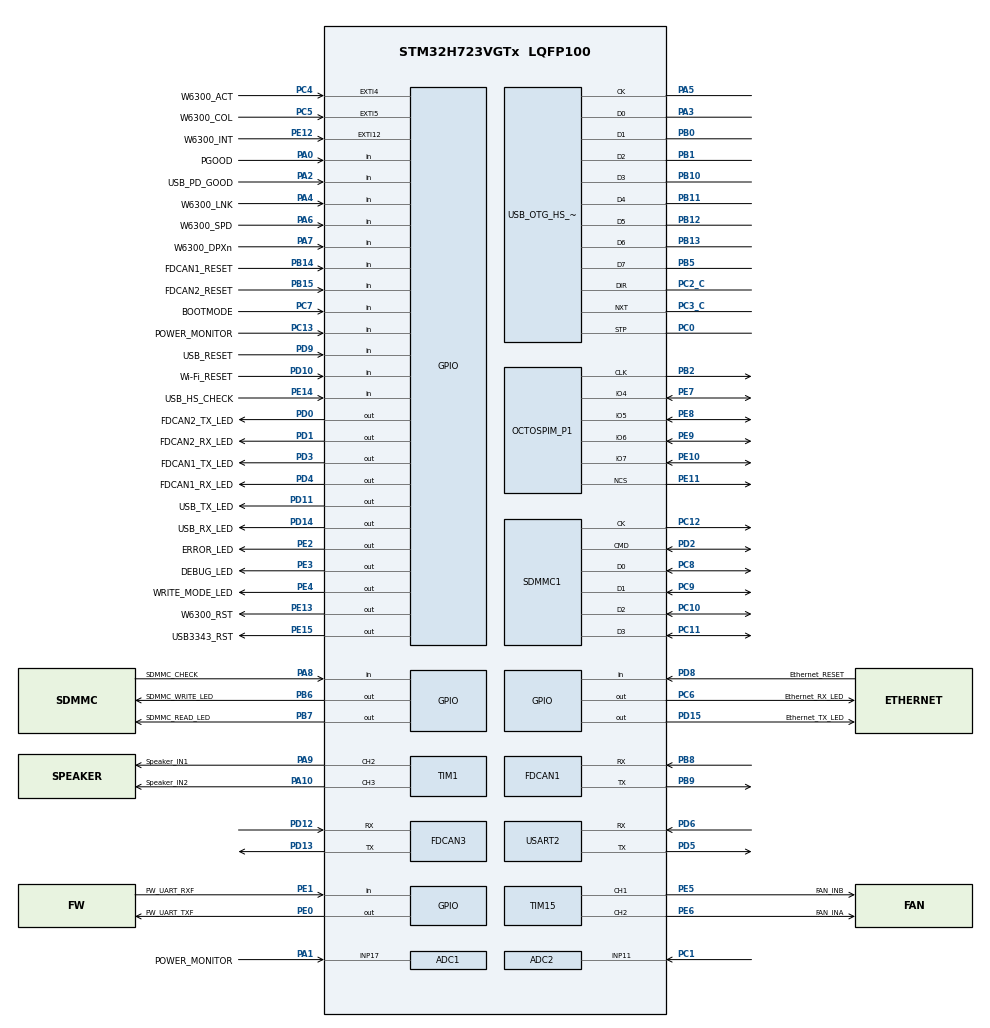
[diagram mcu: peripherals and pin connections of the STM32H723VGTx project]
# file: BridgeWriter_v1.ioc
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ADC1.Channel-0\#ChannelRegularConversion=ADC_CHANNEL_17
ADC1.NbrOfConversionFlag=1
ADC1.OffsetNumber-0\#ChannelRegularConversion=ADC_OFFSET_NONE
ADC1.OffsetSignedSaturation-0\#ChannelRegularConversion=DISABLE
ADC1.Rank-0\#ChannelRegularConversion=1
ADC1.SamplingTime-0\#ChannelRegularConversion=ADC_SAMPLETIME_1CYCLE_5
ADC1.master=1
ADC2.Channel-0\#ChannelRegularConversion=ADC_CHANNEL_11
ADC2.NbrOfConversionFlag=1
ADC2.OffsetNumber-0\#ChannelRegularConversion=ADC_OFFSET_NONE
ADC2.OffsetSignedSaturation-0\#ChannelRegularConversion=DISABLE
ADC2.Rank-0\#ChannelRegularConversion=1
ADC2.SamplingTime-0\#ChannelRegularConversion=ADC_SAMPLETIME_1CYCLE_5
CORTEX_M7.default_mode_Activation=1
FDCAN1.CalculateBaudRateNominal=1000000
FDCAN1.CalculateTimeBitNominal=1000
FDCAN1.CalculateTimeQuantumNominal=50.0
FDCAN1.FrameFormat=FDCAN_FRAME_FD_NO_BRS
FDCAN1.NominalPrescaler=4
FDCAN1.NominalTimeSeg1=15
FDCAN1.NominalTimeSeg2=4
FDCAN1.RxBufferSize=FDCAN_DATA_BYTES_64
FDCAN1.RxFifo0ElmtSize=FDCAN_DATA_BYTES_64
FDCAN1.RxFifo0ElmtsNbr=20
FDCAN1.RxFifo1ElmtSize=FDCAN_DATA_BYTES_64
FDCAN1.RxFifo1ElmtsNbr=20
FDCAN1.TxElmtSize=FDCAN_DATA_BYTES_64
FDCAN1.TxEventsNbr=32
FDCAN3.CalculateBaudRateNominal=1000000
FDCAN3.CalculateTimeBitNominal=1000
FDCAN3.CalculateTimeQuantumNominal=50.0
FDCAN3.FrameFormat=FDCAN_FRAME_FD_NO_BRS
FDCAN3.NominalPrescaler=4
FDCAN3.NominalTimeSeg1=15
FDCAN3.NominalTimeSeg2=4
FDCAN3.RxBufferSize=FDCAN_DATA_BYTES_64
FDCAN3.RxFifo0ElmtSize=FDCAN_DATA_BYTES_64
FDCAN3.RxFifo1ElmtSize=FDCAN_DATA_BYTES_64
FDCAN3.TxElmtSize=FDCAN_DATA_BYTES_64
FDCAN3.TxEventsNbr=32
Mcu.Family=STM32H7
Mcu.Name=STM32H723VGTx
Mcu.Package=LQFP100
NVIC.EXTI15_10_IRQn=true\:0\:0\:false\:false\:true\:true\:true\:true
NVIC.EXTI4_IRQn=true\:0\:0\:false\:false\:true\:true\:true\:true
NVIC.EXTI9_5_IRQn=true\:0\:0\:false\:false\:true\:true\:true\:true
NVIC.FDCAN1_IT0_IRQn=true\:0\:0\:false\:false\:true\:true\:true\:true
NVIC.FDCAN1_IT1_IRQn=true\:0\:0\:false\:false\:true\:true\:true\:true
NVIC.FDCAN3_IT0_IRQn=true\:0\:0\:false\:false\:true\:true\:true\:true
NVIC.FDCAN3_IT1_IRQn=true\:0\:0\:false\:false\:true\:true\:true\:true
NVIC.PriorityGroup=NVIC_PRIORITYGROUP_4
NVIC.RTC_WKUP_IRQn=true\:0\:0\:false\:false\:true\:true\:true\:true
NVIC.TIM6_DAC_IRQn=true\:0\:0\:false\:false\:true\:true\:true\:true
NVIC.TIM7_IRQn=true\:0\:0\:false\:false\:true\:true\:true\:true
PA0.GPIO_Label=PGOOD
PA0.Signal=GPIO_Input
PA1.GPIO_Label=POWER_MONITOR
PA1.Mode=IN17-Single-Ended
PA1.Signal=ADC1_INP17
PA10.GPIO_Label=Speaker_IN2
PA10.GPIO_Speed=GPIO_SPEED_FREQ_MEDIUM
PA10.Signal=S_TIM1_CH3
PA13(JTMS/SWDIO).Mode=Serial_Wire
PA13(JTMS/SWDIO).Signal=DEBUG_JTMS-SWDIO
PA14(JTCK/SWCLK).Mode=Serial_Wire
PA14(JTCK/SWCLK).Signal=DEBUG_JTCK-SWCLK
PA2.GPIO_Label=USB_PD_GOOD
PA2.Signal=GPIO_Input
PA3.Mode=Device_HS
PA3.Signal=USB_OTG_HS_ULPI_D0
PA4.GPIO_Label=W6300_LNK
PA4.Signal=GPIO_Input
PA5.Mode=Device_HS
PA5.Signal=USB_OTG_HS_ULPI_CK
PA6.GPIO_Label=W6300_SPD
PA6.Signal=GPIO_Input
PA7.GPIO_Label=W6300_DPXn
PA7.Signal=GPIO_Input
PA8.GPIO_Label=SDMMC_CHECK
PA8.Signal=GPIO_Input
PA9.GPIO_Label=Speaker_IN1
PA9.GPIO_Speed=GPIO_SPEED_FREQ_MEDIUM
PA9.Signal=S_TIM1_CH2
PB0.Mode=Device_HS
PB0.Signal=USB_OTG_HS_ULPI_D1
PB1.Mode=Device_HS
PB1.Signal=USB_OTG_HS_ULPI_D2
PB10.Mode=Device_HS
PB10.Signal=USB_OTG_HS_ULPI_D3
PB11.Mode=Device_HS
PB11.Signal=USB_OTG_HS_ULPI_D4
PB12.Mode=Device_HS
PB12.Signal=USB_OTG_HS_ULPI_D5
PB13.Mode=Device_HS
PB13.Signal=USB_OTG_HS_ULPI_D6
PB14.GPIO_Label=FDCAN1_RESET
PB14.Signal=GPIO_Input
PB15.GPIO_Label=FDCAN2_RESET
PB15.Signal=GPIO_Input
PB2.Mode=O1_P1_CLK
PB2.Signal=OCTOSPIM_P1_CLK
PB5.Mode=Device_HS
PB5.Signal=USB_OTG_HS_ULPI_D7
PB6.GPIO_Label=SDMMC_WRITE_LED
PB6.Signal=GPIO_Output
PB7.GPIO_Label=SDMMC_READ_LED
PB7.Signal=GPIO_Output
PB8.Mode=FDCAN_Activate
PB8.Signal=FDCAN1_RX
PB9.Mode=FDCAN_Activate
PB9.Signal=FDCAN1_TX
PC0.Mode=Device_HS
PC0.Signal=USB_OTG_HS_ULPI_STP
PC1.Signal=ADCx_INP11
PC10.Mode=SD_4_bits_Wide_bus
PC10.Signal=SDMMC1_D2
PC11.Mode=SD_4_bits_Wide_bus
PC11.Signal=SDMMC1_D3
PC12.Mode=SD_4_bits_Wide_bus
PC12.Signal=SDMMC1_CK
PC13.GPIO_Label=POWER_MONITOR
PC13.Signal=GPIO_Input
PC14-OSC32_IN.Mode=LSE-External-Oscillator
PC14-OSC32_IN.Signal=RCC_OSC32_IN
PC15-OSC32_OUT.Mode=LSE-External-Oscillator
PC15-OSC32_OUT.Signal=RCC_OSC32_OUT
PC2_C.Mode=Device_HS
PC2_C.Signal=USB_OTG_HS_ULPI_DIR
PC3_C.Mode=Device_HS
PC3_C.Signal=USB_OTG_HS_ULPI_NXT
PC4.GPIO_Label=W6300_ACT
PC4.GPIO_ModeDefaultEXTI=GPIO_MODE_IT_RISING_FALLING
PC4.Signal=GPXTI4
PC5.GPIO_Label=W6300_COL
PC5.Signal=GPXTI5
PC6.GPIO_Label=Ethernet_RX_LED
PC6.Signal=GPIO_Output
PC7.GPIO_Label=BOOTMODE
PC7.Signal=GPIO_Input
PC8.Mode=SD_4_bits_Wide_bus
PC8.Signal=SDMMC1_D0
PC9.Mode=SD_4_bits_Wide_bus
PC9.Signal=SDMMC1_D1
PD0.GPIO_Label=FDCAN2_TX_LED
PD0.Signal=GPIO_Output
PD1.GPIO_Label=FDCAN2_RX_LED
PD1.Signal=GPIO_Output
PD10.GPIO_Label=Wi-Fi_RESET
PD10.Signal=GPIO_Input
PD11.GPIO_Label=USB_TX_LED
PD11.Signal=GPIO_Output
PD12.Mode=FDCAN_Activate
PD12.Signal=FDCAN3_RX
PD13.Mode=FDCAN_Activate
PD13.Signal=FDCAN3_TX
PD14.GPIO_Label=USB_RX_LED
PD14.Signal=GPIO_Output
PD15.GPIO_Label=Ethernet_TX_LED
PD15.Signal=GPIO_Output
PD2.Mode=SD_4_bits_Wide_bus
PD2.Signal=SDMMC1_CMD
PD3.GPIO_Label=FDCAN1_TX_LED
PD3.Signal=GPIO_Output
PD4.GPIO_Label=FDCAN1_RX_LED
PD4.Signal=GPIO_Output
PD5.Mode=Asynchronous
PD5.Signal=USART2_TX
PD6.Mode=Asynchronous
PD6.Signal=USART2_RX
PD8.GPIO_Label=Ethernet_RESET
PD8.Signal=GPIO_Input
PD9.GPIO_Label=USB_RESET
PD9.Signal=GPIO_Input
PE0.GPIO_Label=FW_UART_TXF
PE0.GPIO_Speed=GPIO_SPEED_FREQ_VERY_HIGH
PE0.Signal=GPIO_Output
PE1.GPIO_Label=FW_UART_RXF
PE1.Signal=GPIO_Input
PE10.Mode=OCTOSPI1_IOL_Port1H
PE10.Signal=OCTOSPIM_P1_IO7
PE11.Mode=OCTOSPI1_Port1_NCS
PE11.Signal=OCTOSPIM_P1_NCS
PE12.GPIO_Label=W6300_INT
PE12.GPIO_ModeDefaultEXTI=GPIO_MODE_IT_RISING_FALLING
PE12.Signal=GPXTI12
PE13.GPIO_Label=W6300_RST
PE13.GPIO_Speed=GPIO_SPEED_FREQ_VERY_HIGH
PE13.Signal=GPIO_Output
PE14.GPIO_Label=USB_HS_CHECK
PE14.Signal=GPIO_Input
PE15.GPIO_Label=USB3343_RST
PE15.GPIO_Speed=GPIO_SPEED_FREQ_VERY_HIGH
PE15.Signal=GPIO_Output
PE2.GPIO_Label=ERROR_LED
PE2.Signal=GPIO_Output
PE3.GPIO_Label=DEBUG_LED
PE3.Signal=GPIO_Output
PE4.GPIO_Label=WRITE_MODE_LED
PE4.Signal=GPIO_Output
PE5.GPIO_Label=FAN_INB
PE5.GPIO_Speed=GPIO_SPEED_FREQ_MEDIUM
PE5.Signal=S_TIM15_CH1
PE6.GPIO_Label=FAN_INA
PE6.GPIO_Speed=GPIO_SPEED_FREQ_MEDIUM
PE6.Signal=S_TIM15_CH2
PE7.Mode=OCTOSPI1_IOL_Port1H
PE7.Signal=OCTOSPIM_P1_IO4
PE8.Mode=OCTOSPI1_IOL_Port1H
PE8.Signal=OCTOSPIM_P1_IO5
PE9.Mode=OCTOSPI1_IOL_Port1H
PE9.Signal=OCTOSPIM_P1_IO6
PH0-OSC_IN.Mode=HSE-External-Clock-Source
PH0-OSC_IN.Signal=RCC_OSC_IN
ProjectManager.HeapSize=0x200
ProjectManager.StackSize=0x400
ProjectManager.TargetToolchain=CMake
RCC.ADCCLockSelection=RCC_ADCCLKSOURCE_CLKP
RCC.ADCFreq_Value=64000000
RCC.APB1Freq_Value=137500000
RCC.APB2Freq_Value=137500000
RCC.APB3Freq_Value=137500000
RCC.APB4Freq_Value=137500000
RCC.CSI_VALUE=4000000
RCC.CortexFreq_Value=550000000
RCC.Cortex_Div=SYSTICK_CLKSOURCE_HCLK
RCC.D1CPRE=RCC_SYSCLK_DIV1
RCC.D1PPRE=RCC_APB3_DIV2
RCC.D2PPRE1=RCC_APB1_DIV2
RCC.D2PPRE2=RCC_APB2_DIV2
RCC.D3PPRE=RCC_APB4_DIV2
RCC.DFSDMCLockSelection=RCC_DFSDM1CLKSOURCE_D2PCLK1
RCC.DIVM1=5
RCC.DIVM2=5
RCC.DIVM3=5
RCC.DIVN1=55
RCC.DIVN2=48
RCC.DIVN3=48
RCC.DIVP1=1
RCC.DIVP2=2
RCC.DIVP3=2
RCC.DIVQ1=2
RCC.DIVQ2=6
RCC.DIVQ3=4
RCC.DIVR1=2
RCC.DIVR2=2
RCC.DIVR3=2
RCC.EXTERNAL_CLOCK_VALUE=12288000
RCC.FDCANCLockSelection=RCC_FDCANCLKSOURCE_PLL2
RCC.FMCCLockSelection=RCC_FMCCLKSOURCE_D1HCLK
RCC.HCLKFreq_Value=275000000
RCC.HPRE=RCC_HCLK_DIV2
RCC.HSE_VALUE=50000000
RCC.HSI_VALUE=64000000
RCC.LPTIM1CLockSelection=RCC_LPTIM1CLKSOURCE_D2PCLK1
RCC.LPTIM2CLockSelection=RCC_LPTIM2CLKSOURCE_D3PCLK1
RCC.LPUART1CLockSelection=RCC_LPUART1CLKSOURCE_HSI
RCC.PLLSourceVirtual=RCC_PLLSOURCE_HSE
RCC.QSPICLockSelection=RCC_OSPICLKSOURCE_PLL2
RCC.RCC_MCO1Source=RCC_MCO1SOURCE_HSI
RCC.RTCClockSelection=RCC_RTCCLKSOURCE_LSE
RCC.SAI4ACLockSelection=RCC_SAI4ACLKSOURCE_PLL
RCC.SAI4BCLockSelection=RCC_SAI4BCLKSOURCE_PLL
RCC.SDMMC1CLockSelection=RCC_SDMMCCLKSOURCE_PLL2
RCC.SPI123CLockSelection=RCC_SPI123CLKSOURCE_PLL
RCC.SPI6CLockSelection=RCC_SPI6CLKSOURCE_D3PCLK1
RCC.SYSCLKFreq_VALUE=550000000
RCC.SYSCLKSource=RCC_SYSCLKSOURCE_PLLCLK
RCC.Spi45ClockSelection=RCC_SPI45CLKSOURCE_D2PCLK1
RCC.USART234578CLockSelection=RCC_USART234578CLKSOURCE_PLL3
RCC.USBCLockSelection=RCC_USBCLKSOURCE_HSI48
RCC.USBFreq_Value=48000000
RTC.WakeUpClock-WakeUp=RTC_WAKEUPCLOCK_CK_SPRE_16BITS
SH.ADCx_INP11.0=ADC2_INP11,IN11-Single-Ended
SH.S_TIM15_CH1.0=TIM15_CH1,PWM Generation1 CH1
SH.S_TIM15_CH2.0=TIM15_CH2,PWM Generation2 CH2
SH.S_TIM1_CH2.0=TIM1_CH2,PWM Generation2 CH2
SH.S_TIM1_CH3.0=TIM1_CH3,PWM Generation3 CH3
TIM1.Channel-PWM\ Generation2\ CH2=TIM_CHANNEL_2
TIM1.Channel-PWM\ Generation3\ CH3=TIM_CHANNEL_3
TIM15.Channel-PWM\ Generation1\ CH1=TIM_CHANNEL_1
TIM15.Channel-PWM\ Generation2\ CH2=TIM_CHANNEL_2
TIM6.Period=1000
TIM6.Prescaler=275
TIM7.Period=20
TIM7.Prescaler=275
USART2.VirtualMode-Asynchronous=VM_ASYNC
USB_OTG_HS.VirtualMode-Device_HS=Device_HS
VP_MEMORYMAP_VS_MEMORYMAP.Mode=CurAppReg
VP_OCTOSPI1_VS_octo.Mode=octo_mode
VP_RTC_VS_RTC_Activate.Mode=RTC_Enabled
VP_RTC_VS_RTC_WakeUp_intern.Mode=WakeUp
VP_TIM6_VS_ClockSourceINT.Mode=Enable_Timer
VP_TIM7_VS_ClockSourceINT.Mode=Enable_Timer
board=custom

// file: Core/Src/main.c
/* USER CODE BEGIN Header */
/**
  ******************************************************************************
  * @file           : main.c
  * @brief          : Main program body
  ******************************************************************************
  * @attention
  *
  * Copyright (c) 2026 STMicroelectronics.
  * All rights reserved.
  *
  * This software is licensed under terms that can be found in the LICENSE file
  * in the root directory of this software component.
  * If no LICENSE file comes with this software, it is provided AS-IS.
  *
  ******************************************************************************
  */
/* USER CODE END Header */
#include "main.h"

/* USER CODE BEGIN Includes */
#include "HEADER_INCLUDE.h"
/* USER CODE END Includes */

ADC_HandleTypeDef hadc1;
ADC_HandleTypeDef hadc2;

FDCAN_HandleTypeDef hfdcan1;
FDCAN_HandleTypeDef hfdcan3;

OSPI_HandleTypeDef hospi1;

RTC_HandleTypeDef hrtc;

SD_HandleTypeDef hsd1;

TIM_HandleTypeDef htim1;
TIM_HandleTypeDef htim6;
TIM_HandleTypeDef htim7;
TIM_HandleTypeDef htim15;

UART_HandleTypeDef huart2;

PCD_HandleTypeDef hpcd_USB_OTG_HS;

void SystemClock_Config(void);
void PeriphCommonClock_Config(void);
static void MPU_Config(void);
static void MX_GPIO_Init(void);
static void MX_FDCAN1_Init(void);
static void MX_FDCAN3_Init(void);
static void MX_OCTOSPI1_Init(void);
static void MX_RTC_Init(void);
static void MX_SDMMC1_SD_Init(void);
static void MX_USB_OTG_HS_PCD_Init(void);
static void MX_ADC1_Init(void);
static void MX_ADC2_Init(void);
static void MX_USART2_UART_Init(void);
static void MX_TIM1_Init(void);
static void MX_TIM6_Init(void);
static void MX_TIM7_Init(void);
static void MX_TIM15_Init(void);

int main(void)
{

  /* MPU Configuration--------------------------------------------------------*/
  MPU_Config();

  /* MCU Configuration--------------------------------------------------------*/

  /* Reset of all peripherals, Initializes the Flash interface and the Systick. */
  HAL_Init();

  /* Configure the system clock */
  SystemClock_Config();

  /* Configure the peripherals common clocks */
  PeriphCommonClock_Config();

  /* Initialize all configured peripherals */
  MX_GPIO_Init();
  MX_FDCAN1_Init();
  MX_FDCAN3_Init();
  MX_OCTOSPI1_Init();
  MX_RTC_Init();
  MX_SDMMC1_SD_Init();
  MX_USB_OTG_HS_PCD_Init();
  MX_ADC1_Init();
  MX_ADC2_Init();
  MX_USART2_UART_Init();
  MX_TIM1_Init();
  MX_TIM6_Init();
  MX_TIM7_Init();
  MX_TIM15_Init();
  /* USER CODE BEGIN 2 */
  Maidui3_Setup();
  /* USER CODE END 2 */

  /* Infinite loop */
  while (1)
  {

  }
}

void SystemClock_Config(void)
{
  RCC_OscInitTypeDef RCC_OscInitStruct = {0};
  RCC_ClkInitTypeDef RCC_ClkInitStruct = {0};

  /** Supply configuration update enable
  */
  HAL_PWREx_ConfigSupply(PWR_LDO_SUPPLY);

  /** Configure the main internal regulator output voltage
  */
  __HAL_PWR_VOLTAGESCALING_CONFIG(PWR_REGULATOR_VOLTAGE_SCALE0);

  while(!__HAL_PWR_GET_FLAG(PWR_FLAG_VOSRDY)) {}

  /** Configure LSE Drive Capability
  */
  HAL_PWR_EnableBkUpAccess();
  __HAL_RCC_LSEDRIVE_CONFIG(RCC_LSEDRIVE_LOW);

  /** Initializes the RCC Oscillators according to the specified parameters
  * in the RCC_OscInitTypeDef structure.
  */
  RCC_OscInitStruct.OscillatorType = RCC_OSCILLATORTYPE_HSI48|RCC_OSCILLATORTYPE_HSI
                              |RCC_OSCILLATORTYPE_HSE|RCC_OSCILLATORTYPE_LSE;
  RCC_OscInitStruct.HSEState = RCC_HSE_BYPASS;
  RCC_OscInitStruct.LSEState = RCC_LSE_ON;
  RCC_OscInitStruct.HSIState = RCC_HSI_DIV1;
  RCC_OscInitStruct.HSICalibrationValue = 64;
  RCC_OscInitStruct.HSI48State = RCC_HSI48_ON;
  RCC_OscInitStruct.PLL.PLLState = RCC_PLL_ON;
  RCC_OscInitStruct.PLL.PLLSource = RCC_PLLSOURCE_HSE;
  RCC_OscInitStruct.PLL.PLLM = 5;
  RCC_OscInitStruct.PLL.PLLN = 55;
  RCC_OscInitStruct.PLL.PLLP = 1;
  RCC_OscInitStruct.PLL.PLLQ = 2;
  RCC_OscInitStruct.PLL.PLLR = 2;
  RCC_OscInitStruct.PLL.PLLRGE = RCC_PLL1VCIRANGE_3;
  RCC_OscInitStruct.PLL.PLLVCOSEL = RCC_PLL1VCOWIDE;
  RCC_OscInitStruct.PLL.PLLFRACN = 0;
  if (HAL_RCC_OscConfig(&RCC_OscInitStruct) != HAL_OK)
  {
    Error_Handler();
  }

  /** Initializes the CPU, AHB and APB buses clocks
  */
  RCC_ClkInitStruct.ClockType = RCC_CLOCKTYPE_HCLK|RCC_CLOCKTYPE_SYSCLK
                              |RCC_CLOCKTYPE_PCLK1|RCC_CLOCKTYPE_PCLK2
                              |RCC_CLOCKTYPE_D3PCLK1|RCC_CLOCKTYPE_D1PCLK1;
  RCC_ClkInitStruct.SYSCLKSource = RCC_SYSCLKSOURCE_PLLCLK;
  RCC_ClkInitStruct.SYSCLKDivider = RCC_SYSCLK_DIV1;
  RCC_ClkInitStruct.AHBCLKDivider = RCC_HCLK_DIV2;
  RCC_ClkInitStruct.APB3CLKDivider = RCC_APB3_DIV2;
  RCC_ClkInitStruct.APB1CLKDivider = RCC_APB1_DIV2;
  RCC_ClkInitStruct.APB2CLKDivider = RCC_APB2_DIV2;
  RCC_ClkInitStruct.APB4CLKDivider = RCC_APB4_DIV2;

  if (HAL_RCC_ClockConfig(&RCC_ClkInitStruct, FLASH_LATENCY_3) != HAL_OK)
  {
    Error_Handler();
  }
}

void PeriphCommonClock_Config(void)
{
  RCC_PeriphCLKInitTypeDef PeriphClkInitStruct = {0};

  /** Initializes the peripherals clock
  */
  PeriphClkInitStruct.PeriphClockSelection = RCC_PERIPHCLK_OSPI|RCC_PERIPHCLK_SDMMC
                              |RCC_PERIPHCLK_FDCAN|RCC_PERIPHCLK_CKPER;
  PeriphClkInitStruct.PLL2.PLL2M = 5;
  PeriphClkInitStruct.PLL2.PLL2N = 48;
  PeriphClkInitStruct.PLL2.PLL2P = 2;
  PeriphClkInitStruct.PLL2.PLL2Q = 6;
  PeriphClkInitStruct.PLL2.PLL2R = 2;
  PeriphClkInitStruct.PLL2.PLL2RGE = RCC_PLL2VCIRANGE_3;
  PeriphClkInitStruct.PLL2.PLL2VCOSEL = RCC_PLL2VCOWIDE;
  PeriphClkInitStruct.PLL2.PLL2FRACN = 0;
  PeriphClkInitStruct.OspiClockSelection = RCC_OSPICLKSOURCE_PLL2;
  PeriphClkInitStruct.SdmmcClockSelection = RCC_SDMMCCLKSOURCE_PLL2;
  PeriphClkInitStruct.CkperClockSelection = RCC_CLKPSOURCE_HSI;
  PeriphClkInitStruct.FdcanClockSelection = RCC_FDCANCLKSOURCE_PLL2;
  if (HAL_RCCEx_PeriphCLKConfig(&PeriphClkInitStruct) != HAL_OK)
  {
    Error_Handler();
  }
}

static void MX_ADC1_Init(void)
{

  ADC_MultiModeTypeDef multimode = {0};
  ADC_ChannelConfTypeDef sConfig = {0};

  /** Common config
  */
  hadc1.Instance = ADC1;
  hadc1.Init.ClockPrescaler = ADC_CLOCK_ASYNC_DIV1;
  hadc1.Init.Resolution = ADC_RESOLUTION_16B;
  hadc1.Init.ScanConvMode = ADC_SCAN_DISABLE;
  hadc1.Init.EOCSelection = ADC_EOC_SINGLE_CONV;
  hadc1.Init.LowPowerAutoWait = DISABLE;
  hadc1.Init.ContinuousConvMode = DISABLE;
  hadc1.Init.NbrOfConversion = 1;
  hadc1.Init.DiscontinuousConvMode = DISABLE;
  hadc1.Init.ExternalTrigConv = ADC_SOFTWARE_START;
  hadc1.Init.ExternalTrigConvEdge = ADC_EXTERNALTRIGCONVEDGE_NONE;
  hadc1.Init.ConversionDataManagement = ADC_CONVERSIONDATA_DR;
  hadc1.Init.Overrun = ADC_OVR_DATA_PRESERVED;
  hadc1.Init.LeftBitShift = ADC_LEFTBITSHIFT_NONE;
  hadc1.Init.OversamplingMode = DISABLE;
  hadc1.Init.Oversampling.Ratio = 1;
  if (HAL_ADC_Init(&hadc1) != HAL_OK)
  {
    Error_Handler();
  }

  /** Configure the ADC multi-mode
  */
  multimode.Mode = ADC_MODE_INDEPENDENT;
  if (HAL_ADCEx_MultiModeConfigChannel(&hadc1, &multimode) != HAL_OK)
  {
    Error_Handler();
  }

  /** Configure Regular Channel
  */
  sConfig.Channel = ADC_CHANNEL_17;
  sConfig.Rank = ADC_REGULAR_RANK_1;
  sConfig.SamplingTime = ADC_SAMPLETIME_1CYCLE_5;
  sConfig.SingleDiff = ADC_SINGLE_ENDED;
  sConfig.OffsetNumber = ADC_OFFSET_NONE;
  sConfig.Offset = 0;
  sConfig.OffsetSignedSaturation = DISABLE;
  if (HAL_ADC_ConfigChannel(&hadc1, &sConfig) != HAL_OK)
  {
    Error_Handler();
  }

}

static void MX_ADC2_Init(void)
{

  ADC_ChannelConfTypeDef sConfig = {0};

  /** Common config
  */
  hadc2.Instance = ADC2;
  hadc2.Init.ClockPrescaler = ADC_CLOCK_ASYNC_DIV1;
  hadc2.Init.Resolution = ADC_RESOLUTION_16B;
  hadc2.Init.ScanConvMode = ADC_SCAN_DISABLE;
  hadc2.Init.EOCSelection = ADC_EOC_SINGLE_CONV;
  hadc2.Init.LowPowerAutoWait = DISABLE;
  hadc2.Init.ContinuousConvMode = DISABLE;
  hadc2.Init.NbrOfConversion = 1;
  hadc2.Init.DiscontinuousConvMode = DISABLE;
  hadc2.Init.ExternalTrigConv = ADC_SOFTWARE_START;
  hadc2.Init.ExternalTrigConvEdge = ADC_EXTERNALTRIGCONVEDGE_NONE;
  hadc2.Init.ConversionDataManagement = ADC_CONVERSIONDATA_DR;
  hadc2.Init.Overrun = ADC_OVR_DATA_PRESERVED;
  hadc2.Init.LeftBitShift = ADC_LEFTBITSHIFT_NONE;
  hadc2.Init.OversamplingMode = DISABLE;
  hadc2.Init.Oversampling.Ratio = 1;
  if (HAL_ADC_Init(&hadc2) != HAL_OK)
  {
    Error_Handler();
  }

  /** Configure Regular Channel
  */
  sConfig.Channel = ADC_CHANNEL_11;
  sConfig.Rank = ADC_REGULAR_RANK_1;
  sConfig.SamplingTime = ADC_SAMPLETIME_1CYCLE_5;
  sConfig.SingleDiff = ADC_SINGLE_ENDED;
  sConfig.OffsetNumber = ADC_OFFSET_NONE;
  sConfig.Offset = 0;
  sConfig.OffsetSignedSaturation = DISABLE;
  if (HAL_ADC_ConfigChannel(&hadc2, &sConfig) != HAL_OK)
  {
    Error_Handler();
  }

}

static void MX_FDCAN1_Init(void)
{

  hfdcan1.Instance = FDCAN1;
  hfdcan1.Init.FrameFormat = FDCAN_FRAME_FD_NO_BRS;
  hfdcan1.Init.Mode = FDCAN_MODE_NORMAL;
  hfdcan1.Init.AutoRetransmission = DISABLE;
  hfdcan1.Init.TransmitPause = DISABLE;
  hfdcan1.Init.ProtocolException = DISABLE;
  hfdcan1.Init.NominalPrescaler = 4;
  hfdcan1.Init.NominalSyncJumpWidth = 1;
  hfdcan1.Init.NominalTimeSeg1 = 15;
  hfdcan1.Init.NominalTimeSeg2 = 4;
  hfdcan1.Init.DataPrescaler = 1;
  hfdcan1.Init.DataSyncJumpWidth = 1;
  hfdcan1.Init.DataTimeSeg1 = 1;
  hfdcan1.Init.DataTimeSeg2 = 1;
  hfdcan1.Init.MessageRAMOffset = 0;
  hfdcan1.Init.StdFiltersNbr = 0;
  hfdcan1.Init.ExtFiltersNbr = 0;
  hfdcan1.Init.RxFifo0ElmtsNbr = 20;
  hfdcan1.Init.RxFifo0ElmtSize = FDCAN_DATA_BYTES_64;
  hfdcan1.Init.RxFifo1ElmtsNbr = 20;
  hfdcan1.Init.RxFifo1ElmtSize = FDCAN_DATA_BYTES_64;
  hfdcan1.Init.RxBuffersNbr = 0;
  hfdcan1.Init.RxBufferSize = FDCAN_DATA_BYTES_64;
  hfdcan1.Init.TxEventsNbr = 32;
  hfdcan1.Init.TxBuffersNbr = 0;
  hfdcan1.Init.TxFifoQueueElmtsNbr = 0;
  hfdcan1.Init.TxFifoQueueMode = FDCAN_TX_FIFO_OPERATION;
  hfdcan1.Init.TxElmtSize = FDCAN_DATA_BYTES_64;
  if (HAL_FDCAN_Init(&hfdcan1) != HAL_OK)
  {
    Error_Handler();
  }

}

static void MX_FDCAN3_Init(void)
{

  hfdcan3.Instance = FDCAN3;
  hfdcan3.Init.FrameFormat = FDCAN_FRAME_FD_NO_BRS;
  hfdcan3.Init.Mode = FDCAN_MODE_NORMAL;
  hfdcan3.Init.AutoRetransmission = DISABLE;
  hfdcan3.Init.TransmitPause = DISABLE;
  hfdcan3.Init.ProtocolException = DISABLE;
  hfdcan3.Init.NominalPrescaler = 4;
  hfdcan3.Init.NominalSyncJumpWidth = 1;
  hfdcan3.Init.NominalTimeSeg1 = 15;
  hfdcan3.Init.NominalTimeSeg2 = 4;
  hfdcan3.Init.DataPrescaler = 1;
  hfdcan3.Init.DataSyncJumpWidth = 1;
  hfdcan3.Init.DataTimeSeg1 = 1;
  hfdcan3.Init.DataTimeSeg2 = 1;
  hfdcan3.Init.MessageRAMOffset = 0;
  hfdcan3.Init.StdFiltersNbr = 0;
  hfdcan3.Init.ExtFiltersNbr = 0;
  hfdcan3.Init.RxFifo0ElmtsNbr = 0;
  hfdcan3.Init.RxFifo0ElmtSize = FDCAN_DATA_BYTES_64;
  hfdcan3.Init.RxFifo1ElmtsNbr = 0;
  hfdcan3.Init.RxFifo1ElmtSize = FDCAN_DATA_BYTES_64;
  hfdcan3.Init.RxBuffersNbr = 0;
  hfdcan3.Init.RxBufferSize = FDCAN_DATA_BYTES_64;
  hfdcan3.Init.TxEventsNbr = 32;
  hfdcan3.Init.TxBuffersNbr = 0;
  hfdcan3.Init.TxFifoQueueElmtsNbr = 0;
  hfdcan3.Init.TxFifoQueueMode = FDCAN_TX_FIFO_OPERATION;
  hfdcan3.Init.TxElmtSize = FDCAN_DATA_BYTES_64;
  if (HAL_FDCAN_Init(&hfdcan3) != HAL_OK)
  {
    Error_Handler();
  }

}

static void MX_OCTOSPI1_Init(void)
{

  OSPIM_CfgTypeDef sOspiManagerCfg = {0};

  /* OCTOSPI1 parameter configuration*/
  hospi1.Instance = OCTOSPI1;
  hospi1.Init.FifoThreshold = 1;
  hospi1.Init.DualQuad = HAL_OSPI_DUALQUAD_DISABLE;
  hospi1.Init.MemoryType = HAL_OSPI_MEMTYPE_MICRON;
  hospi1.Init.DeviceSize = 32;
  hospi1.Init.ChipSelectHighTime = 1;
  hospi1.Init.FreeRunningClock = HAL_OSPI_FREERUNCLK_DISABLE;
  hospi1.Init.ClockMode = HAL_OSPI_CLOCK_MODE_0;
  hospi1.Init.WrapSize = HAL_OSPI_WRAP_NOT_SUPPORTED;
  hospi1.Init.ClockPrescaler = 1;
  hospi1.Init.SampleShifting = HAL_OSPI_SAMPLE_SHIFTING_NONE;
  hospi1.Init.DelayHoldQuarterCycle = HAL_OSPI_DHQC_DISABLE;
  hospi1.Init.ChipSelectBoundary = 0;
  hospi1.Init.DelayBlockBypass = HAL_OSPI_DELAY_BLOCK_BYPASSED;
  hospi1.Init.MaxTran = 0;
  hospi1.Init.Refresh = 0;
  if (HAL_OSPI_Init(&hospi1) != HAL_OK)
  {
    Error_Handler();
  }
  sOspiManagerCfg.ClkPort = 1;
  sOspiManagerCfg.NCSPort = 1;
  sOspiManagerCfg.IOLowPort = HAL_OSPIM_IOPORT_1_HIGH;
  if (HAL_OSPIM_Config(&hospi1, &sOspiManagerCfg, HAL_OSPI_TIMEOUT_DEFAULT_VALUE) != HAL_OK)
  {
    Error_Handler();
  }

}

static void MX_RTC_Init(void)
{

  /** Initialize RTC Only
  */
  hrtc.Instance = RTC;
  hrtc.Init.HourFormat = RTC_HOURFORMAT_24;
  hrtc.Init.AsynchPrediv = 127;
  hrtc.Init.SynchPrediv = 255;
  hrtc.Init.OutPut = RTC_OUTPUT_DISABLE;
  hrtc.Init.OutPutPolarity = RTC_OUTPUT_POLARITY_HIGH;
  hrtc.Init.OutPutType = RTC_OUTPUT_TYPE_OPENDRAIN;
  hrtc.Init.OutPutRemap = RTC_OUTPUT_REMAP_NONE;
  if (HAL_RTC_Init(&hrtc) != HAL_OK)
  {
    Error_Handler();
  }

  /** Enable the WakeUp
  */
  if (HAL_RTCEx_SetWakeUpTimer_IT(&hrtc, 0, RTC_WAKEUPCLOCK_CK_SPRE_16BITS) != HAL_OK)
  {
    Error_Handler();
  }

}

static void MX_SDMMC1_SD_Init(void)
{

  hsd1.Instance = SDMMC1;
  hsd1.Init.ClockEdge = SDMMC_CLOCK_EDGE_RISING;
  hsd1.Init.ClockPowerSave = SDMMC_CLOCK_POWER_SAVE_DISABLE;
  hsd1.Init.BusWide = SDMMC_BUS_WIDE_4B;
  hsd1.Init.HardwareFlowControl = SDMMC_HARDWARE_FLOW_CONTROL_DISABLE;
  hsd1.Init.ClockDiv = 0;
  if (HAL_SD_Init(&hsd1) != HAL_OK)
  {
    Error_Handler();
  }

}

static void MX_TIM1_Init(void)
{

  TIM_MasterConfigTypeDef sMasterConfig = {0};
  TIM_OC_InitTypeDef sConfigOC = {0};
  TIM_BreakDeadTimeConfigTypeDef sBreakDeadTimeConfig = {0};

  htim1.Instance = TIM1;
  htim1.Init.Prescaler = 0;
  htim1.Init.CounterMode = TIM_COUNTERMODE_UP;
  htim1.Init.Period = 65535;
  htim1.Init.ClockDivision = TIM_CLOCKDIVISION_DIV1;
  htim1.Init.RepetitionCounter = 0;
  htim1.Init.AutoReloadPreload = TIM_AUTORELOAD_PRELOAD_DISABLE;
  if (HAL_TIM_PWM_Init(&htim1) != HAL_OK)
  {
    Error_Handler();
  }
  sMasterConfig.MasterOutputTrigger = TIM_TRGO_RESET;
  sMasterConfig.MasterOutputTrigger2 = TIM_TRGO2_RESET;
  sMasterConfig.MasterSlaveMode = TIM_MASTERSLAVEMODE_DISABLE;
  if (HAL_TIMEx_MasterConfigSynchronization(&htim1, &sMasterConfig) != HAL_OK)
  {
    Error_Handler();
  }
  sConfigOC.OCMode = TIM_OCMODE_PWM1;
  sConfigOC.Pulse = 0;
  sConfigOC.OCPolarity = TIM_OCPOLARITY_HIGH;
  sConfigOC.OCNPolarity = TIM_OCNPOLARITY_HIGH;
  sConfigOC.OCFastMode = TIM_OCFAST_DISABLE;
  sConfigOC.OCIdleState = TIM_OCIDLESTATE_RESET;
  sConfigOC.OCNIdleState = TIM_OCNIDLESTATE_RESET;
  if (HAL_TIM_PWM_ConfigChannel(&htim1, &sConfigOC, TIM_CHANNEL_2) != HAL_OK)
  {
    Error_Handler();
  }
  if (HAL_TIM_PWM_ConfigChannel(&htim1, &sConfigOC, TIM_CHANNEL_3) != HAL_OK)
  {
    Error_Handler();
  }
  sBreakDeadTimeConfig.OffStateRunMode = TIM_OSSR_DISABLE;
  sBreakDeadTimeConfig.OffStateIDLEMode = TIM_OSSI_DISABLE;
  sBreakDeadTimeConfig.LockLevel = TIM_LOCKLEVEL_OFF;
  sBreakDeadTimeConfig.DeadTime = 0;
  sBreakDeadTimeConfig.BreakState = TIM_BREAK_DISABLE;
  sBreakDeadTimeConfig.BreakPolarity = TIM_BREAKPOLARITY_HIGH;
  sBreakDeadTimeConfig.BreakFilter = 0;
  sBreakDeadTimeConfig.Break2State = TIM_BREAK2_DISABLE;
  sBreakDeadTimeConfig.Break2Polarity = TIM_BREAK2POLARITY_HIGH;
  sBreakDeadTimeConfig.Break2Filter = 0;
  sBreakDeadTimeConfig.AutomaticOutput = TIM_AUTOMATICOUTPUT_DISABLE;
  if (HAL_TIMEx_ConfigBreakDeadTime(&htim1, &sBreakDeadTimeConfig) != HAL_OK)
  {
    Error_Handler();
  }
  HAL_TIM_MspPostInit(&htim1);

}

static void MX_TIM6_Init(void)
{

  TIM_MasterConfigTypeDef sMasterConfig = {0};

  htim6.Instance = TIM6;
  htim6.Init.Prescaler = 275;
  htim6.Init.CounterMode = TIM_COUNTERMODE_UP;
  htim6.Init.Period = 1000;
  htim6.Init.AutoReloadPreload = TIM_AUTORELOAD_PRELOAD_DISABLE;
  if (HAL_TIM_Base_Init(&htim6) != HAL_OK)
  {
    Error_Handler();
  }
  sMasterConfig.MasterOutputTrigger = TIM_TRGO_RESET;
  sMasterConfig.MasterSlaveMode = TIM_MASTERSLAVEMODE_DISABLE;
  if (HAL_TIMEx_MasterConfigSynchronization(&htim6, &sMasterConfig) != HAL_OK)
  {
    Error_Handler();
  }

}

static void MX_TIM7_Init(void)
{

  TIM_MasterConfigTypeDef sMasterConfig = {0};

  htim7.Instance = TIM7;
  htim7.Init.Prescaler = 275;
  htim7.Init.CounterMode = TIM_COUNTERMODE_UP;
  htim7.Init.Period = 20;
  htim7.Init.AutoReloadPreload = TIM_AUTORELOAD_PRELOAD_DISABLE;
  if (HAL_TIM_Base_Init(&htim7) != HAL_OK)
  {
    Error_Handler();
  }
  sMasterConfig.MasterOutputTrigger = TIM_TRGO_RESET;
  sMasterConfig.MasterSlaveMode = TIM_MASTERSLAVEMODE_DISABLE;
  if (HAL_TIMEx_MasterConfigSynchronization(&htim7, &sMasterConfig) != HAL_OK)
  {
    Error_Handler();
  }

}

static void MX_TIM15_Init(void)
{

  TIM_MasterConfigTypeDef sMasterConfig = {0};
  TIM_OC_InitTypeDef sConfigOC = {0};
  TIM_BreakDeadTimeConfigTypeDef sBreakDeadTimeConfig = {0};

  htim15.Instance = TIM15;
  htim15.Init.Prescaler = 0;
  htim15.Init.CounterMode = TIM_COUNTERMODE_UP;
  htim15.Init.Period = 65535;
  htim15.Init.ClockDivision = TIM_CLOCKDIVISION_DIV1;
  htim15.Init.RepetitionCounter = 0;
  htim15.Init.AutoReloadPreload = TIM_AUTORELOAD_PRELOAD_DISABLE;
  if (HAL_TIM_PWM_Init(&htim15) != HAL_OK)
  {
    Error_Handler();
  }
  sMasterConfig.MasterOutputTrigger = TIM_TRGO_RESET;
  sMasterConfig.MasterSlaveMode = TIM_MASTERSLAVEMODE_DISABLE;
  if (HAL_TIMEx_MasterConfigSynchronization(&htim15, &sMasterConfig) != HAL_OK)
  {
    Error_Handler();
  }
  sConfigOC.OCMode = TIM_OCMODE_PWM1;
  sConfigOC.Pulse = 0;
  sConfigOC.OCPolarity = TIM_OCPOLARITY_HIGH;
  sConfigOC.OCNPolarity = TIM_OCNPOLARITY_HIGH;
  sConfigOC.OCFastMode = TIM_OCFAST_DISABLE;
  sConfigOC.OCIdleState = TIM_OCIDLESTATE_RESET;
  sConfigOC.OCNIdleState = TIM_OCNIDLESTATE_RESET;
  if (HAL_TIM_PWM_ConfigChannel(&htim15, &sConfigOC, TIM_CHANNEL_1) != HAL_OK)
  {
    Error_Handler();
  }
  if (HAL_TIM_PWM_ConfigChannel(&htim15, &sConfigOC, TIM_CHANNEL_2) != HAL_OK)
  {
    Error_Handler();
  }
  sBreakDeadTimeConfig.OffStateRunMode = TIM_OSSR_DISABLE;
  sBreakDeadTimeConfig.OffStateIDLEMode = TIM_OSSI_DISABLE;
  sBreakDeadTimeConfig.LockLevel = TIM_LOCKLEVEL_OFF;
  sBreakDeadTimeConfig.DeadTime = 0;
  sBreakDeadTimeConfig.BreakState = TIM_BREAK_DISABLE;
  sBreakDeadTimeConfig.BreakPolarity = TIM_BREAKPOLARITY_HIGH;
  sBreakDeadTimeConfig.BreakFilter = 0;
  sBreakDeadTimeConfig.AutomaticOutput = TIM_AUTOMATICOUTPUT_DISABLE;
  if (HAL_TIMEx_ConfigBreakDeadTime(&htim15, &sBreakDeadTimeConfig) != HAL_OK)
  {
    Error_Handler();
  }
  HAL_TIM_MspPostInit(&htim15);

}

static void MX_USART2_UART_Init(void)
{

  huart2.Instance = USART2;
  huart2.Init.BaudRate = 115200;
  huart2.Init.WordLength = UART_WORDLENGTH_8B;
  huart2.Init.StopBits = UART_STOPBITS_1;
  huart2.Init.Parity = UART_PARITY_NONE;
  huart2.Init.Mode = UART_MODE_TX_RX;
  huart2.Init.HwFlowCtl = UART_HWCONTROL_NONE;
  huart2.Init.OverSampling = UART_OVERSAMPLING_16;
  huart2.Init.OneBitSampling = UART_ONE_BIT_SAMPLE_DISABLE;
  huart2.Init.ClockPrescaler = UART_PRESCALER_DIV1;
  huart2.AdvancedInit.AdvFeatureInit = UART_ADVFEATURE_NO_INIT;
  if (HAL_UART_Init(&huart2) != HAL_OK)
  {
    Error_Handler();
  }
  if (HAL_UARTEx_SetTxFifoThreshold(&huart2, UART_TXFIFO_THRESHOLD_1_8) != HAL_OK)
  {
    Error_Handler();
  }
  if (HAL_UARTEx_SetRxFifoThreshold(&huart2, UART_RXFIFO_THRESHOLD_1_8) != HAL_OK)
  {
    Error_Handler();
  }
  if (HAL_UARTEx_DisableFifoMode(&huart2) != HAL_OK)
  {
    Error_Handler();
  }

}

static void MX_USB_OTG_HS_PCD_Init(void)
{

  hpcd_USB_OTG_HS.Instance = USB_OTG_HS;
  hpcd_USB_OTG_HS.Init.dev_endpoints = 9;
  hpcd_USB_OTG_HS.Init.speed = PCD_SPEED_HIGH;
  hpcd_USB_OTG_HS.Init.dma_enable = DISABLE;
  hpcd_USB_OTG_HS.Init.phy_itface = USB_OTG_ULPI_PHY;
  hpcd_USB_OTG_HS.Init.Sof_enable = DISABLE;
  hpcd_USB_OTG_HS.Init.low_power_enable = DISABLE;
  hpcd_USB_OTG_HS.Init.lpm_enable = DISABLE;
  hpcd_USB_OTG_HS.Init.vbus_sensing_enable = DISABLE;
  hpcd_USB_OTG_HS.Init.use_dedicated_ep1 = DISABLE;
  hpcd_USB_OTG_HS.Init.use_external_vbus = DISABLE;
  if (HAL_PCD_Init(&hpcd_USB_OTG_HS) != HAL_OK)
  {
    Error_Handler();
  }

}

static void MX_GPIO_Init(void)
{
  GPIO_InitTypeDef GPIO_InitStruct = {0};

  /* GPIO Ports Clock Enable */
  __HAL_RCC_GPIOE_CLK_ENABLE();
  __HAL_RCC_GPIOC_CLK_ENABLE();
  __HAL_RCC_GPIOH_CLK_ENABLE();
  __HAL_RCC_GPIOA_CLK_ENABLE();
  __HAL_RCC_GPIOB_CLK_ENABLE();
  __HAL_RCC_GPIOD_CLK_ENABLE();

  /*Configure GPIO pin Output Level */
  HAL_GPIO_WritePin(GPIOE, ERROR_LED_Pin|DEBUG_LED_Pin|WRITE_MODE_LED_Pin|W6300_RST_Pin
                          |USB3343_RST_Pin|FW_UART_TXF_Pin, GPIO_PIN_RESET);

  /*Configure GPIO pin Output Level */
  HAL_GPIO_WritePin(GPIOD, USB_TX_LED_Pin|USB_RX_LED_Pin|Ethernet_TX_LED_Pin|FDCAN2_TX_LED_Pin
                          |FDCAN2_RX_LED_Pin|FDCAN1_TX_LED_Pin|FDCAN1_RX_LED_Pin, GPIO_PIN_RESET);

  /*Configure GPIO pin Output Level */
  HAL_GPIO_WritePin(Ethernet_RX_LED_GPIO_Port, Ethernet_RX_LED_Pin, GPIO_PIN_RESET);

  /*Configure GPIO pin Output Level */
  HAL_GPIO_WritePin(GPIOB, SDMMC_WRITE_LED_Pin|SDMMC_READ_LED_Pin, GPIO_PIN_RESET);

  /*Configure GPIO pins : ERROR_LED_Pin DEBUG_LED_Pin WRITE_MODE_LED_Pin */
  GPIO_InitStruct.Pin = ERROR_LED_Pin|DEBUG_LED_Pin|WRITE_MODE_LED_Pin;
  GPIO_InitStruct.Mode = GPIO_MODE_OUTPUT_PP;
  GPIO_InitStruct.Pull = GPIO_NOPULL;
  GPIO_InitStruct.Speed = GPIO_SPEED_FREQ_LOW;
  HAL_GPIO_Init(GPIOE, &GPIO_InitStruct);

  /*Configure GPIO pins : POWER_MONITOR_Pin BOOTMODE_Pin */
  GPIO_InitStruct.Pin = POWER_MONITOR_Pin|BOOTMODE_Pin;
  GPIO_InitStruct.Mode = GPIO_MODE_INPUT;
  GPIO_InitStruct.Pull = GPIO_NOPULL;
  HAL_GPIO_Init(GPIOC, &GPIO_InitStruct);

  /*Configure GPIO pins : PGOOD_Pin USB_PD_GOOD_Pin W6300_LNK_Pin W6300_SPD_Pin
                           W6300_DPXn_Pin SDMMC_CHECK_Pin */
  GPIO_InitStruct.Pin = PGOOD_Pin|USB_PD_GOOD_Pin|W6300_LNK_Pin|W6300_SPD_Pin
                          |W6300_DPXn_Pin|SDMMC_CHECK_Pin;
  GPIO_InitStruct.Mode = GPIO_MODE_INPUT;
  GPIO_InitStruct.Pull = GPIO_NOPULL;
  HAL_GPIO_Init(GPIOA, &GPIO_InitStruct);

  /*Configure GPIO pin : W6300_ACT_Pin */
  GPIO_InitStruct.Pin = W6300_ACT_Pin;
  GPIO_InitStruct.Mode = GPIO_MODE_IT_RISING_FALLING;
  GPIO_InitStruct.Pull = GPIO_NOPULL;
  HAL_GPIO_Init(W6300_ACT_GPIO_Port, &GPIO_InitStruct);

  /*Configure GPIO pin : W6300_COL_Pin */
  GPIO_InitStruct.Pin = W6300_COL_Pin;
  GPIO_InitStruct.Mode = GPIO_MODE_IT_RISING;
  GPIO_InitStruct.Pull = GPIO_NOPULL;
  HAL_GPIO_Init(W6300_COL_GPIO_Port, &GPIO_InitStruct);

  /*Configure GPIO pin : W6300_INT_Pin */
  GPIO_InitStruct.Pin = W6300_INT_Pin;
  GPIO_InitStruct.Mode = GPIO_MODE_IT_RISING_FALLING;
  GPIO_InitStruct.Pull = GPIO_NOPULL;
  HAL_GPIO_Init(W6300_INT_GPIO_Port, &GPIO_InitStruct);

  /*Configure GPIO pins : W6300_RST_Pin USB3343_RST_Pin FW_UART_TXF_Pin */
  GPIO_InitStruct.Pin = W6300_RST_Pin|USB3343_RST_Pin|FW_UART_TXF_Pin;
  GPIO_InitStruct.Mode = GPIO_MODE_OUTPUT_PP;
  GPIO_InitStruct.Pull = GPIO_NOPULL;
  GPIO_InitStruct.Speed = GPIO_SPEED_FREQ_VERY_HIGH;
  HAL_GPIO_Init(GPIOE, &GPIO_InitStruct);

  /*Configure GPIO pins : USB_HS_CHECK_Pin FW_UART_RXF_Pin */
  GPIO_InitStruct.Pin = USB_HS_CHECK_Pin|FW_UART_RXF_Pin;
  GPIO_InitStruct.Mode = GPIO_MODE_INPUT;
  GPIO_InitStruct.Pull = GPIO_NOPULL;
  HAL_GPIO_Init(GPIOE, &GPIO_InitStruct);

  /*Configure GPIO pins : FDCAN1_RESET_Pin FDCAN2_RESET_Pin */
  GPIO_InitStruct.Pin = FDCAN1_RESET_Pin|FDCAN2_RESET_Pin;
  GPIO_InitStruct.Mode = GPIO_MODE_INPUT;
  GPIO_InitStruct.Pull = GPIO_NOPULL;
  HAL_GPIO_Init(GPIOB, &GPIO_InitStruct);

  /*Configure GPIO pins : Ethernet_RESET_Pin USB_RESET_Pin Wi_Fi_RESET_Pin */
  GPIO_InitStruct.Pin = Ethernet_RESET_Pin|USB_RESET_Pin|Wi_Fi_RESET_Pin;
  GPIO_InitStruct.Mode = GPIO_MODE_INPUT;
  GPIO_InitStruct.Pull = GPIO_NOPULL;
  HAL_GPIO_Init(GPIOD, &GPIO_InitStruct);

  /*Configure GPIO pins : USB_TX_LED_Pin USB_RX_LED_Pin Ethernet_TX_LED_Pin FDCAN2_TX_LED_Pin
                           FDCAN2_RX_LED_Pin FDCAN1_TX_LED_Pin FDCAN1_RX_LED_Pin */
  GPIO_InitStruct.Pin = USB_TX_LED_Pin|USB_RX_LED_Pin|Ethernet_TX_LED_Pin|FDCAN2_TX_LED_Pin
                          |FDCAN2_RX_LED_Pin|FDCAN1_TX_LED_Pin|FDCAN1_RX_LED_Pin;
  GPIO_InitStruct.Mode = GPIO_MODE_OUTPUT_PP;
  GPIO_InitStruct.Pull = GPIO_NOPULL;
  GPIO_InitStruct.Speed = GPIO_SPEED_FREQ_LOW;
  HAL_GPIO_Init(GPIOD, &GPIO_InitStruct);

  /*Configure GPIO pin : Ethernet_RX_LED_Pin */
  GPIO_InitStruct.Pin = Ethernet_RX_LED_Pin;
  GPIO_InitStruct.Mode = GPIO_MODE_OUTPUT_PP;
  GPIO_InitStruct.Pull = GPIO_NOPULL;
  GPIO_InitStruct.Speed = GPIO_SPEED_FREQ_LOW;
  HAL_GPIO_Init(Ethernet_RX_LED_GPIO_Port, &GPIO_InitStruct);

  /*Configure GPIO pins : SDMMC_WRITE_LED_Pin SDMMC_READ_LED_Pin */
  GPIO_InitStruct.Pin = SDMMC_WRITE_LED_Pin|SDMMC_READ_LED_Pin;
  GPIO_InitStruct.Mode = GPIO_MODE_OUTPUT_PP;
  GPIO_InitStruct.Pull = GPIO_NOPULL;
  GPIO_InitStruct.Speed = GPIO_SPEED_FREQ_LOW;
  HAL_GPIO_Init(GPIOB, &GPIO_InitStruct);

  /* EXTI interrupt init*/
  HAL_NVIC_SetPriority(W6300_ACT_EXTI_IRQn, 0, 0);
  HAL_NVIC_EnableIRQ(W6300_ACT_EXTI_IRQn);

  HAL_NVIC_SetPriority(W6300_COL_EXTI_IRQn, 0, 0);
  HAL_NVIC_EnableIRQ(W6300_COL_EXTI_IRQn);

  HAL_NVIC_SetPriority(W6300_INT_EXTI_IRQn, 0, 0);
  HAL_NVIC_EnableIRQ(W6300_INT_EXTI_IRQn);

}

 /* MPU Configuration */

void MPU_Config(void)
{
  MPU_Region_InitTypeDef MPU_InitStruct = {0};

  /* Disables the MPU */
  HAL_MPU_Disable();

  /** Initializes and configures the Region and the memory to be protected
  */
  MPU_InitStruct.Enable = MPU_REGION_ENABLE;
  MPU_InitStruct.Number = MPU_REGION_NUMBER0;
  MPU_InitStruct.BaseAddress = 0x0;
  MPU_InitStruct.Size = MPU_REGION_SIZE_4GB;
  MPU_InitStruct.SubRegionDisable = 0x87;
  MPU_InitStruct.TypeExtField = MPU_TEX_LEVEL0;
  MPU_InitStruct.AccessPermission = MPU_REGION_NO_ACCESS;
  MPU_InitStruct.DisableExec = MPU_INSTRUCTION_ACCESS_DISABLE;
  MPU_InitStruct.IsShareable = MPU_ACCESS_SHAREABLE;
  MPU_InitStruct.IsCacheable = MPU_ACCESS_NOT_CACHEABLE;
  MPU_InitStruct.IsBufferable = MPU_ACCESS_NOT_BUFFERABLE;

  HAL_MPU_ConfigRegion(&MPU_InitStruct);
  /* Enables the MPU */
  HAL_MPU_Enable(MPU_PRIVILEGED_DEFAULT);

}

void Error_Handler(void)
{
  __disable_irq();
  while (1)
  {
  }
}
